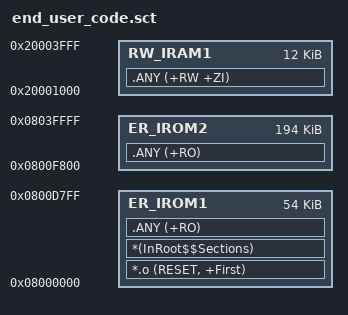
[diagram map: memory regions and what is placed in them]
; *************************************************************
; *** Scatter-Loading Description File generated by uVision ***
; *************************************************************

LR_IROM1 0x08000000 0x0000D800  {    ; load region size_region
  ER_IROM1 0x08000000 0x0000D800  {  ; load address = execution address
   *.o (RESET, +First)
   *(InRoot$$Sections)
   .ANY (+RO)
  }
  RW_IRAM1 0x20001000 0x00003000  {  ; RW data
   .ANY (+RW +ZI)
  }
  
 ; 0x20000000 ~ 0x20000FFF   RAM reserved for SLIB code
  
}

; 0x0800D800 ~ 0x0800F7FF is SLIB area

LR_IROM2 0x0800F800 0x00030800  {    ; load region size_region
  ER_IROM2 0x0800F800 0x00030800  {  ; load address = execution address
   .ANY (+RO)
  }
}



